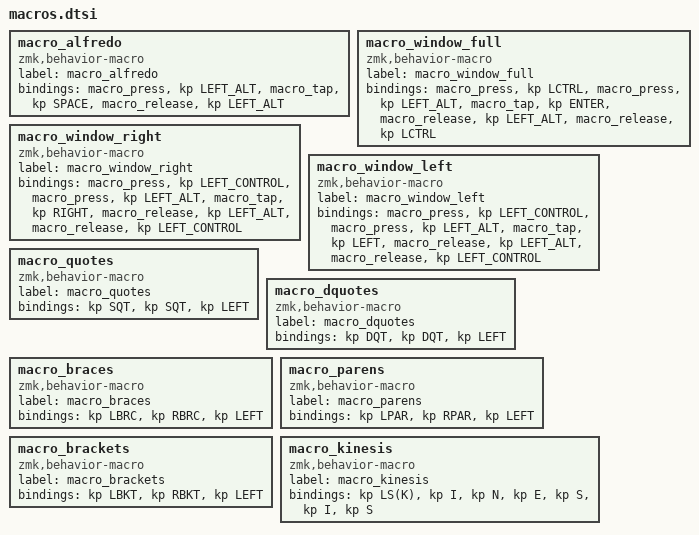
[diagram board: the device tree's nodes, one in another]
macro_alfredo: macro_alfredo {
compatible = "zmk,behavior-macro";
label = "macro_alfredo";
#binding-cells = <0>;
bindings = <&macro_press &kp LEFT_ALT>, <&macro_tap &kp SPACE>, <&macro_release &kp LEFT_ALT>;
};
macro_window_full: macro_window_full {
compatible = "zmk,behavior-macro";
label = "macro_window_full";
#binding-cells = <0>;
bindings = <&macro_press &kp LCTRL>, <&macro_press &kp LEFT_ALT>, <&macro_tap &kp ENTER>, <&macro_release &kp LEFT_ALT>, <&macro_release &kp LCTRL>;
};
macro_window_right: macro_window_right {
compatible = "zmk,behavior-macro";
label = "macro_window_right";
#binding-cells = <0>;
bindings = <&macro_press &kp LEFT_CONTROL>, <&macro_press &kp LEFT_ALT>, <&macro_tap &kp RIGHT>, <&macro_release &kp LEFT_ALT>, <&macro_release &kp LEFT_CONTROL>;
};
macro_window_left: macro_window_left {
compatible = "zmk,behavior-macro";
label = "macro_window_left";
#binding-cells = <0>;
bindings = <&macro_press &kp LEFT_CONTROL>, <&macro_press &kp LEFT_ALT>, <&macro_tap &kp LEFT>, <&macro_release &kp LEFT_ALT>, <&macro_release &kp LEFT_CONTROL>;
};
macro_quotes: macro_quotes{
compatible = "zmk,behavior-macro";
label = "macro_quotes";
#binding-cells = <0>;
bindings = <&kp SQT>, <&kp SQT>, <&kp LEFT>;
};
macro_dquotes: macro_dquotes{
compatible = "zmk,behavior-macro";
label = "macro_dquotes";
#binding-cells = <0>;
bindings = <&kp DQT>, <&kp DQT>, <&kp LEFT>;
};
macro_braces: macro_braces{
compatible = "zmk,behavior-macro";
label = "macro_braces";
#binding-cells = <0>;
bindings = <&kp LBRC>, <&kp RBRC>, <&kp LEFT>;
};
macro_parens: macro_parens{
compatible = "zmk,behavior-macro";
label = "macro_parens";
#binding-cells = <0>;
bindings = <&kp LPAR>, <&kp RPAR>, <&kp LEFT>;
};
macro_brackets: macro_brackets{
compatible = "zmk,behavior-macro";
label = "macro_brackets";
#binding-cells = <0>;
bindings = <&kp LBKT>, <&kp RBKT>, <&kp LEFT>;
};
macro_kinesis: macro_kinesis{
compatible = "zmk,behavior-macro";
label = "macro_kinesis";
#binding-cells = <0>;
bindings = <&kp LS(K)>, <&kp I>, <&kp N>, <&kp E>, <&kp S>, <&kp I>, <&kp S>;
};
